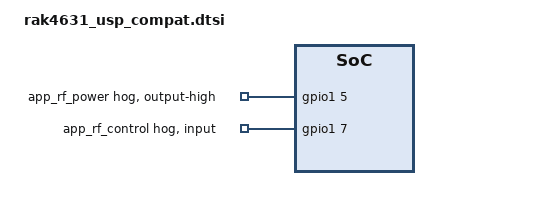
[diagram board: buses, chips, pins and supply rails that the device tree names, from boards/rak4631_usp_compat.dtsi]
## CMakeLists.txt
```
# SPDX-License-Identifier: Apache-2.0

cmake_minimum_required(VERSION 3.20.0)
find_package(Zephyr REQUIRED HINTS $ENV{ZEPHYR_BASE})
project(rzi_lorawan_counter)

target_sources(app PRIVATE src/main.c)
```

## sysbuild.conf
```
# SPDX-License-Identifier: Apache-2.0

SB_CONFIG_BOOTLOADER_MCUBOOT=y
SB_CONFIG_MERGED_HEX_FILES=y
```

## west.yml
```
# SPDX-License-Identifier: Apache-2.0
# Customer application manifest. RZI is consumed as an independent west project;
# Zephyr and the default USP backend dependencies are imported from the RZI
# manifest, so the Zephyr revision follows the one RZI is validated against.

manifest:
  version: "1.2"

  self:
    path: app

  remotes:
    - name: rzi-origin
      url-base: https://github.com/DanielCao0

  projects:
    - name: rzi
      repo-path: RZI
      remote: rzi-origin
      revision: develop
      import: true
```

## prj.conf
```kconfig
# Own USP + LBM LoRaWAN app (not Zephyr CONFIG_LORAWAN / loramac-node).

# --- Board peripherals ---
CONFIG_GPIO=y                          # LED and SX1262 DIO, reset, and busy signals
CONFIG_SPI=y                           # SX1262 bus
CONFIG_SERIAL=y                        # UART subsystem; this board uses USB CDC

# --- Console (RAK4631 overlay selects board_cdc_acm_uart) ---
CONFIG_CONSOLE=y
CONFIG_UART_CONSOLE=y                  # Route printk and LOG through the UART console
CONFIG_UART_LINE_CTRL=y                # CDC DTR used by wait_usb_console()
CONFIG_USE_SEGGER_RTT=n                # Keep logs off the J-Link RTT backend

# --- USB CDC ACM virtual serial console (board fragments set USB strings/logging) ---
CONFIG_USB_DEVICE_STACK_NEXT=y         # Next-generation USB device stack
CONFIG_CDC_ACM_SERIAL_INITIALIZE_AT_BOOT=y
# Delay logging until USB enumeration completes. Keep numeric assignments on their own lines.
CONFIG_LOG_PROCESS_THREAD_STARTUP_DELAY_MS=4000

# --- Logging and memory ---
CONFIG_LOG=y
CONFIG_LOG_BACKEND_SHOW_COLOR=n        # CDC output is not a color terminal
CONFIG_LOG_BUFFER_SIZE=4096
CONFIG_HEAP_MEM_POOL_SIZE=8192
CONFIG_MAIN_STACK_SIZE=8192

# --- Storage, power management, and random numbers ---
CONFIG_FLASH=y                         # LBM stores the join session in NVM
CONFIG_PM_DEVICE=y                     # Device power management used by the radio driver
CONFIG_TEST_RANDOM_GENERATOR=y         # Software PRNG used for values such as Join DevNonce

# --- Disable native Zephyr LoRa/LoRaWAN to keep exclusive ownership of the SX1262 ---
CONFIG_LORA=n
CONFIG_LORAWAN=n

# --- RZI C SDK (backend dependencies are owned by its Kconfig) ---
CONFIG_RZI=y
CONFIG_RZI_LORAWAN=y
CONFIG_RZI_POWER=y
CONFIG_RZI_MCUBOOT=y
CONFIG_STREAM_FLASH=y
CONFIG_IMG_MANAGER=y
CONFIG_LORA_BASICS_MODEM_DRIVERS_EVENT_TRIGGER_NO_THREAD=y  # Handle DIO IRQs without an intermediate thread

# --- Thread priorities (negative values are cooperative; lower values run first) ---
# USP (-4) runs before main (-2) whenever main yields.
CONFIG_MAIN_THREAD_PRIORITY=-2
CONFIG_USP_MAIN_THREAD_PRIORITY=-4
```

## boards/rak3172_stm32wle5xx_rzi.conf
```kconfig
# SPDX-FileCopyrightText: Copyright (c) 2026 RAKwireless
# SPDX-License-Identifier: Apache-2.0

# STM32WLE5 has no USB controller; use LPUART1 on PA2/PA3.
CONFIG_USB_DEVICE_STACK_NEXT=n
CONFIG_CDC_ACM_SERIAL_INITIALIZE_AT_BOOT=n
CONFIG_UART_LINE_CTRL=n
CONFIG_LOG_PROCESS_THREAD_STARTUP_DELAY_MS=0
```

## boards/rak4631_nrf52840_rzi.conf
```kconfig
# SPDX-License-Identifier: Apache-2.0

CONFIG_CDC_ACM_SERIAL_PRODUCT_STRING="RAK4631 USP"
CONFIG_USBD_CDC_ACM_LOG_LEVEL_OFF=y
CONFIG_USBD_LOG_LEVEL_OFF=y
```

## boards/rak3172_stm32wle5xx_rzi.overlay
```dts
/* SPDX-License-Identifier: Apache-2.0 */
/*
 * Product credentials and UART console. Radio, partitions and USP
 * compatibility are on the rak3172/stm32wle5xx/rzi variant.
 */

/ {
	aliases {
		led0 = &blue_led;
		led1 = &green_led;
	};

	chosen {
		zephyr,console = &lpuart1;
	};

	zephyr,user {
		/* ChirpStack device RZI_001. */
		user-lorawan-device-eui = <0x74 0x85 0xef 0xc6 0x2c 0xb3 0xcb 0xd3>;
		user-lorawan-join-eui = <0x00 0x00 0x00 0x00 0x00 0x00 0x00 0x00>;
		user-lorawan-gen_app-key = <0x00 0x00 0x00 0x00 0x00 0x00 0x00 0x00
					    0x00 0x00 0x00 0x00 0x00 0x00 0x00 0x00>;
		user-lorawan-app-key = <0x4b 0x9d 0x67 0x65 0x7d 0xa9 0xb6 0x60
					0xf4 0xd4 0xe3 0xdd 0xf2 0xbb 0x71 0x59>;
		user-lorawan-region = "EU_868";
	};
};
```

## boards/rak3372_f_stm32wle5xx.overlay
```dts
/* SPDX-License-Identifier: Apache-2.0 */
/*
 * Product credentials and UART console. Radio, partitions and USP
 * compatibility are on the rak3372_f board.
 */

/ {
	aliases {
		led0 = &led2;
		led1 = &led1;
	};

	chosen {
		zephyr,console = &lpuart1;
	};

	zephyr,user {
		/* ChirpStack device RZI_001. */
		user-lorawan-device-eui = <0x74 0x85 0xef 0xc6 0x2c 0xb3 0xcb 0xd3>;
		user-lorawan-join-eui = <0x00 0x00 0x00 0x00 0x00 0x00 0x00 0x00>;
		user-lorawan-gen_app-key = <0x00 0x00 0x00 0x00 0x00 0x00 0x00 0x00
					    0x00 0x00 0x00 0x00 0x00 0x00 0x00 0x00>;
		user-lorawan-app-key = <0x4b 0x9d 0x67 0x65 0x7d 0xa9 0xb6 0x60
					0xf4 0xd4 0xe3 0xdd 0xf2 0xbb 0x71 0x59>;
		user-lorawan-region = "EU_868";
	};
};
```

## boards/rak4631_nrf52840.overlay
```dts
/*
 * Assign the onboard RAK4631 SX1262 to usp_zephyr.
 *
 * The board DTS already defines &lora (SPI, reset, and busy) and the lora0 alias.
 * The local compatibility include changes its compatible to
 * "semtech,sx1262-new" for the currently pinned USP driver.
 *
 * Replace the credentials under zephyr,user before joining a network.
 */

/* Remove this include when the pinned BSP and USP driver interoperate directly. */
#include "rak4631_usp_compat.dtsi"

/ {
	chosen {
		/* USP threads and HAL locate the radio through this chosen node. */
		zephyr,lorawan-transceiver = &lora;

		/* Route logs through USB CDC; the board default is uart1. */
		zephyr,console = &cdc_acm_uart0;
	};

	aliases {
		/* The board defines only the blue led0; expose the green LED as led1. */
		led1 = &green_led;
	};

	/*
	 * zephyr,user is a standard Zephyr application-data node.
	 * The user-lorawan-* properties form the RZI application credential contract.
	 */
	zephyr,user {
		/* ChirpStack device RZI_001. */
		user-lorawan-device-eui = <0x00 0x00 0x00 0x00 0x00 0x00 0x00 0x00>;
		/* Match this value to the Join EUI configured on the network server. */
		user-lorawan-join-eui = <0x00 0x00 0x00 0x00 0x00 0x00 0x00 0x00>;
		/* GenAppKey for remote multicast; passed to LBM set_appkey. */
		user-lorawan-gen_app-key = <0x00 0x00 0x00 0x00 0x00 0x00 0x00 0x00
					    0x00 0x00 0x00 0x00 0x00 0x00 0x00 0x00>;
		/* OTAA AppKey; LoRaWAN 1.0 uses it as the LBM network key. */
		user-lorawan-app-key = <0x00 0x00 0x00 0x00 0x00 0x00 0x00 0x00
					0x00 0x00 0x00 0x00 0x00 0x00 0x00 0x00>;
		/* EU_868, CN_470, AS_923_GRP1, US_915, ... */
		user-lorawan-region = "EU_868";
	};
};

/* Standard Zephyr USB CDC console. */
&zephyr_udc0 {
	cdc_acm_uart0: cdc_acm_uart0 {
		compatible = "zephyr,cdc-acm-uart";
	};
};
```

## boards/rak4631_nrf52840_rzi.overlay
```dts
/* SPDX-License-Identifier: Apache-2.0 */
/*
 * Product credentials and USB console. Radio, partitions and USP
 * compatibility are on the rak4631/nrf52840/rzi variant.
 */

/ {
	chosen {
		zephyr,console = &board_cdc_acm_uart;
	};

	zephyr,user {
		/* ChirpStack device RZI_001. */
		user-lorawan-device-eui = <0x74 0x85 0xef 0xc6 0x2c 0xb3 0xcb 0xd3>;
		user-lorawan-join-eui = <0x00 0x00 0x00 0x00 0x00 0x00 0x00 0x00>;
		user-lorawan-gen_app-key = <0x00 0x00 0x00 0x00 0x00 0x00 0x00 0x00
					    0x00 0x00 0x00 0x00 0x00 0x00 0x00 0x00>;
		user-lorawan-app-key = <0x4b 0x9d 0x67 0x65 0x7d 0xa9 0xb6 0x60
					0xf4 0xd4 0xe3 0xdd 0xf2 0xbb 0x71 0x59>;
		user-lorawan-region = "EU_868";
	};
};
```

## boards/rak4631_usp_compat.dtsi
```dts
/* SPDX-License-Identifier: Apache-2.0 */
/* Temporary adapter for the pinned RAK4631 BSP and USP SX1262 driver. */
#include <zephyr/dt-bindings/usp/sx126x.h>

/ {
	chosen {
		zephyr,lorawan-transceiver = &lora;
	};
};

&lora {
	compatible = "semtech,sx1262-new";
	dio1-gpios = <&gpio1 15 (GPIO_ACTIVE_HIGH | GPIO_PULL_DOWN)>;
	dio2-as-rf-switch;
	dio3-as-tcxo-control;
	tcxo-voltage = <SX126X_TCXO_SUPPLY_3_3V>;
	tcxo-wakeup-time = <5>;
	reg-mode = <SX126X_REG_MODE_DCDC>;
	/delete-property/ dio2-tx-enable;
	/delete-property/ dio3-tcxo-voltage;
	/delete-property/ tcxo-power-startup-delay-ms;
	/delete-property/ rx-enable-gpios;
};

&gpio1 {
	app_rf_power: app-rf-power {
		gpio-hog;
		gpios = <5 GPIO_ACTIVE_HIGH>;
		output-high;
	};
	app_rf_control: app-rf-control {
		gpio-hog;
		gpios = <7 GPIO_ACTIVE_HIGH>;
		input;
	};
};
```

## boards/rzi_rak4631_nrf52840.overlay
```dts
/* SPDX-License-Identifier: Apache-2.0 */
/*
 * Product credentials and USB console. Radio, partitions and USP
 * compatibility are on the rzi_rak4631 board.
 */

/ {
	chosen {
		zephyr,console = &cdc_acm_uart0;
	};

	zephyr,user {
		/* ChirpStack device RZI_001. */
		user-lorawan-device-eui = <0x74 0x85 0xef 0xc6 0x2c 0xb3 0xcb 0xd3>;
		user-lorawan-join-eui = <0x00 0x00 0x00 0x00 0x00 0x00 0x00 0x00>;
		user-lorawan-gen_app-key = <0x00 0x00 0x00 0x00 0x00 0x00 0x00 0x00
					    0x00 0x00 0x00 0x00 0x00 0x00 0x00 0x00>;
		user-lorawan-app-key = <0x4b 0x9d 0x67 0x65 0x7d 0xa9 0xb6 0x60
					0xf4 0xd4 0xe3 0xdd 0xf2 0xbb 0x71 0x59>;
		user-lorawan-region = "EU_868";
	};
};
```

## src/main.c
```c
/* SPDX-License-Identifier: Apache-2.0 */
/* RZI C API example: OTAA and a confirmed four-byte counter every 5 s. */
#include <errno.h>
#include <rzi/init.h>
#include <rzi/lorawan/lorawan.h>
#include <rzi/power/power.h>
#include <zephyr/devicetree.h>
#include <zephyr/drivers/gpio.h>
#include <zephyr/drivers/uart.h>
#include <zephyr/kernel.h>
#include <zephyr/logging/log.h>
#include <zephyr/sys/atomic.h>

static __maybe_unused void ignore_result(int result)
{
	ARG_UNUSED(result);
}

LOG_MODULE_REGISTER(rzi_app, LOG_LEVEL_INF);
#define PERIOD_MS         5000
#define USER_NODE         DT_PATH(zephyr_user)
#define REGION_NAME(name) DT_CAT(RZI_LORAWAN_REGION_, name)
#define LORAWAN_REGION REGION_NAME(DT_STRING_UNQUOTED(USER_NODE, user_lorawan_region))
/* Region identifiers are C enums; evaluate this condition in C, not in #if. */
#define EU868_DUTY_CYCLE_CHECK (LORAWAN_REGION == RZI_LORAWAN_REGION_EU_868)
#define EVENT_READY       BIT(0)
#define EVENT_JOINED      BIT(1)
#define EVENT_JOIN_FAILED BIT(2)
#define EVENT_ERROR       BIT(3)
static const struct gpio_dt_spec blue = GPIO_DT_SPEC_GET(DT_ALIAS(led0), gpios);
static const struct gpio_dt_spec green = GPIO_DT_SPEC_GET(DT_ALIAS(led1), gpios);
static uint32_t counter;
static atomic_t callback_error;
static atomic_t join_in_progress;
K_MSGQ_DEFINE(lorawan_events, sizeof(uint8_t), 8, 1);

static void green_blink(struct k_timer *timer)
{
	ARG_UNUSED(timer);
	gpio_pin_toggle_dt(&green);
}
static void blue_off_handler(struct k_work *work)
{
	ARG_UNUSED(work);
	gpio_pin_set_dt(&blue, 0);
}
K_TIMER_DEFINE(join_led_timer, green_blink, NULL);
K_WORK_DELAYABLE_DEFINE(blue_off_work, blue_off_handler);

static void blue_off(void)
{
	(void)k_work_cancel_delayable(&blue_off_work);
	gpio_pin_set_dt(&blue, 0);
}
static void joining_leds(void)
{
	blue_off();
	gpio_pin_set_dt(&green, 1);
	k_timer_start(&join_led_timer, K_MSEC(500), K_MSEC(500));
}
static void joined_leds(void)
{
	k_timer_stop(&join_led_timer);
	gpio_pin_set_dt(&green, 1);
	blue_off();
}
static void wait_usb_console(void)
{
	if (!IS_ENABLED(CONFIG_UART_LINE_CTRL)) {
		return;
	}

	const struct device *dev = DEVICE_DT_GET(DT_CHOSEN(zephyr_console));
	uint32_t dtr = 0;
	int64_t deadline = k_uptime_get() + 10000;
	if (!device_is_ready(dev)) {
		return;
	}
	while (!dtr && k_uptime_get() < deadline) {
		(void)uart_line_ctrl_get(dev, UART_LINE_CTRL_DTR, &dtr);
		k_sleep(K_MSEC(100));
	}
}
static int configure_credentials(void)
{
	static const uint8_t dev_eui[] = DT_PROP(USER_NODE, user_lorawan_device_eui);
	static const uint8_t join_eui[] = DT_PROP(USER_NODE, user_lorawan_join_eui);
	static const uint8_t app_key[] = DT_PROP(USER_NODE, user_lorawan_app_key);
	static const uint8_t gen_app_key[] = DT_PROP(USER_NODE, user_lorawan_gen_app_key);
	int rc = rzi_lorawan_set_dev_eui(dev_eui, sizeof(dev_eui));

	if (!rc) {
		rc = rzi_lorawan_set_app_eui(join_eui, sizeof(join_eui));
	}
	if (!rc) {
		rc = rzi_lorawan_set_app_key(app_key, sizeof(app_key));
	}
	if (!rc) {
		rc = rzi_lorawan_set_gen_app_key(gen_app_key, sizeof(gen_app_key));
	}
	if (!rc) {
		rc = rzi_lorawan_set_activation(RZI_LORAWAN_ACTIVATION_OTAA);
	}
	return rc;
}
static int64_t send_counter(void)
{
	uint8_t data[4] = {counter >> 24, counter >> 16, counter >> 8, counter};
	int rc;

	if (EU868_DUTY_CYCLE_CHECK) {
		int32_t time_ms;

		rc = rzi_lorawan_get_duty_cycle_status(&time_ms);
		if (rc != 0) {
			LOG_WRN("Duty-cycle query failed: %d; retry in %d ms", rc, PERIOD_MS);
			return PERIOD_MS;
		}
		if (time_ms < 0) {
			int64_t wait_ms = -(int64_t)time_ms;

			LOG_INF("Duty cycle limited; retry in %lld ms", (long long)wait_ms);
			return wait_ms;
		}
	}

	rc = rzi_lorawan_send(1, data, sizeof(data), RZI_LORAWAN_MSG_CONFIRMED);
	if (rc) {
		LOG_WRN("uplink not accepted: %d", rc);
		return PERIOD_MS;
	}
	gpio_pin_set_dt(&blue, 1);
	(void)k_work_reschedule(&blue_off_work, K_MSEC(80));
	LOG_INF("confirmed uplink #%u on port 1", counter++);
	return PERIOD_MS;
}

static void on_state_changed(enum rzi_lorawan_state state, void *user_data)
{
	const uint8_t event = EVENT_READY;

	ARG_UNUSED(user_data);
	if (state == RZI_LORAWAN_STATE_READY && !atomic_get(&join_in_progress)) {
		(void)k_msgq_put(&lorawan_events, &event, K_NO_WAIT);
	}
}

static void on_join_done(int status, void *user_data)
{
	const uint8_t event = status == 0 ? EVENT_JOINED : EVENT_JOIN_FAILED;

	ARG_UNUSED(user_data);
	atomic_clear(&join_in_progress);
	(void)k_msgq_put(&lorawan_events, &event, K_NO_WAIT);
}

static void on_send_done(const struct rzi_lorawan_tx_result *result, void *user_data)
{
	ARG_UNUSED(user_data);
	LOG_INF("TXDONE %s", result->status == RZI_LORAWAN_EVENT_TXDONE_CONFIRMED ? "ACK"
			     : result->status == RZI_LORAWAN_EVENT_TXDONE_SENT ? "sent, no ACK"
								     : "not sent");
	blue_off();
}

static void on_downlink(const struct rzi_lorawan_downlink *downlink, void *user_data)
{
	ARG_UNUSED(user_data);
	LOG_INF("DOWNLINK port %u, %u bytes, RSSI %d dBm, SNR %d/4 dB", downlink->port,
		(unsigned int)downlink->size, downlink->rssi_dbm, downlink->snr_quarter_db);
}

static void on_error(int error, void *user_data)
{
	const uint8_t event = EVENT_ERROR;

	ARG_UNUSED(user_data);
	atomic_set(&callback_error, error);
	(void)k_msgq_put(&lorawan_events, &event, K_NO_WAIT);
}

static void on_event(const struct rzi_lorawan_event *event, void *user_data)
{
	switch (event->type) {
	case RZI_LORAWAN_EVENT_READY:
		on_state_changed(RZI_LORAWAN_STATE_READY, user_data);
		break;
	case RZI_LORAWAN_EVENT_STATE_CHANGED:
		on_state_changed(event->state, user_data);
		break;
	case RZI_LORAWAN_EVENT_JOINED:
		on_join_done(0, user_data);
		break;
	case RZI_LORAWAN_EVENT_JOIN_FAILED:
		on_join_done(event->error, user_data);
		break;
	case RZI_LORAWAN_EVENT_TXDONE:
		on_send_done(&event->tx, user_data);
		break;
	case RZI_LORAWAN_EVENT_DOWNDATA:
		on_downlink(&event->downlink, user_data);
		break;
	case RZI_LORAWAN_EVENT_REGIONAL_DUTY_CYCLE:
		LOG_INF("REGIONAL_DUTY_CYCLE: %s", event->duty_cycle_limited ? "limited" : "clear");
		if (EU868_DUTY_CYCLE_CHECK && event->duty_cycle_limited) {
			int32_t time_ms;
			int rc = rzi_lorawan_get_duty_cycle_status(&time_ms);

			if (rc == 0 && time_ms < 0) {
				LOG_INF("Duty-cycle wait remaining: %lld ms", -(long long)time_ms);
			} else if (rc != 0) {
				LOG_WRN("Duty-cycle query failed: %d", rc);
			}
		}
		break;
	case RZI_LORAWAN_EVENT_ERROR:
		on_error(event->error, user_data);
		break;
	default:
		break;
	}
}

static const struct rzi_lorawan_callbacks callbacks = {
	.on_event = on_event,
};

int main(void)
{
	if (!gpio_is_ready_dt(&blue) || !gpio_is_ready_dt(&green)) {
		return -ENODEV;
	}
	int rc = gpio_pin_configure_dt(&blue, GPIO_OUTPUT_INACTIVE);
	if (rc) {
		return rc;
	}
	rc = gpio_pin_configure_dt(&green, GPIO_OUTPUT_INACTIVE);
	if (rc) {
		return rc;
	}
	joining_leds();
	rc = rzi_init();
	if (rc) {
		return rc;
	}
	ignore_result(rzi_power_block(RZI_POWER_BLOCK_TRANSPORT));
	wait_usb_console();
	ignore_result(rzi_power_unblock(RZI_POWER_BLOCK_TRANSPORT));
	LOG_INF("RZI C API example on %s", CONFIG_BOARD_TARGET);
	rc = rzi_lorawan_register_callbacks(&callbacks);
	if (!rc) {
		rc = configure_credentials();
	}
	if (!rc) {
		rc = rzi_lorawan_set_join_backoff_bypass(true);
	}
	if (!rc) {
		rc = rzi_lorawan_init(LORAWAN_REGION);
	}
	if (rc) {
		LOG_ERR("RZI start failed: %d", rc);
		return rc;
	}
	bool ready = false;
	bool joined = false;
	int64_t next_action = 0;
	for (;;) {
		uint8_t events = 0;
		int32_t wait_ms =
			ready ? (int32_t)CLAMP(next_action - k_uptime_get(), 0, PERIOD_MS) : -1;

		(void)k_msgq_get(&lorawan_events, &events,
				 wait_ms < 0 ? K_FOREVER : K_MSEC(wait_ms));
		if (events & EVENT_READY) {
			ready = true;
			joined = false;
			next_action = 0;
			joining_leds();
		}
		if (events & EVENT_JOINED) {
			LOG_INF("JOINED");
			joined = true;
			next_action = 0;
			joined_leds();
		}
		if (events & EVENT_JOIN_FAILED) {
			LOG_WRN("JOINFAIL, retry in 5 s");
			joined = false;
			joining_leds();
			next_action = k_uptime_get() + PERIOD_MS;
		}
		if (events & EVENT_ERROR) {
			int error = (int)atomic_get(&callback_error);

			LOG_ERR("modem error: %d; reboot required", error);
			return error;
		}
		if (ready && k_uptime_get() >= next_action) {
			if (joined) {
				int64_t delay_ms = send_counter();

				next_action = k_uptime_get() + delay_ms;
			} else {
				atomic_set(&join_in_progress, 1);
				rc = rzi_lorawan_join(1, 0, RZI_LORAWAN_JOIN_INTERVAL_DEFAULT, 0);
				if (rc) {
					atomic_clear(&join_in_progress);
					if (rc != -RZI_ERR_BUSY) {
						LOG_WRN("join not accepted: %d", rc);
					}
				}
				next_action = k_uptime_get() + PERIOD_MS;
			}
		}
	}
}
```

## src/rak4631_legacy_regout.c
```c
/* SPDX-License-Identifier: Apache-2.0 */
/* Temporary board compatibility for the currently pinned Zephyr BSP. */

#include <zephyr/init.h>
#include <hal/nrf_power.h>

void board_early_init_hook(void)
{
	if ((nrf_power_mainregstatus_get(NRF_POWER) == NRF_POWER_MAINREGSTATUS_HIGH) &&
	    ((NRF_UICR->REGOUT0 & UICR_REGOUT0_VOUT_Msk) ==
	     (UICR_REGOUT0_VOUT_DEFAULT << UICR_REGOUT0_VOUT_Pos))) {
		NRF_NVMC->CONFIG = NVMC_CONFIG_WEN_Wen << NVMC_CONFIG_WEN_Pos;
		while (NRF_NVMC->READY == NVMC_READY_READY_Busy) {
			;
		}

		NRF_UICR->REGOUT0 =
			(NRF_UICR->REGOUT0 & ~((uint32_t)UICR_REGOUT0_VOUT_Msk)) |
			(UICR_REGOUT0_VOUT_3V3 << UICR_REGOUT0_VOUT_Pos);

		NRF_NVMC->CONFIG = NVMC_CONFIG_WEN_Ren << NVMC_CONFIG_WEN_Pos;
		while (NRF_NVMC->READY == NVMC_READY_READY_Busy) {
			;
		}

		NVIC_SystemReset();
	}
}
```
